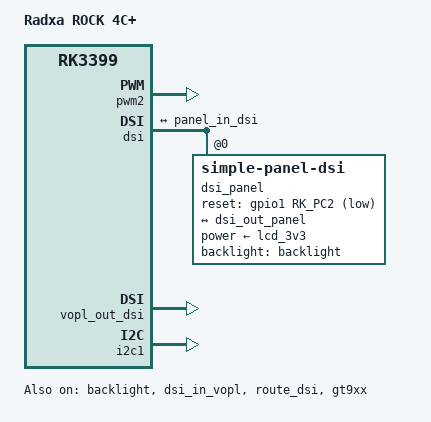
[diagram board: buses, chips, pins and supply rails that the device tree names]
/dts-v1/;
/plugin/;

#include <dt-bindings/gpio/gpio.h>
#include <dt-bindings/pinctrl/rockchip.h>
#include <dt-bindings/display/drm_mipi_dsi.h>

/ {
	model = "Radxa ROCK 4C+";
	compatible = "radxa,rock-4c-plus", "rockchip,rk3399";

	fragment@0 {
		target = <&backlight>;

		__overlay__ {
			status = "okay";
		};
	};

	fragment@1 {
		target = <&pwm2>;

		__overlay__ {
			status = "okay";
		};
	};

	fragment@2 {
		target = <&dsi>;

		__overlay__ {
			status = "okay";
			#address-cells = <1>;
			#size-cells = <0>;

			ports {
				#address-cells = <1>;
				#size-cells = <0>;

				port@1 {
					reg = <1>;
					dsi_out_panel: endpoint {
						remote-endpoint = <&panel_in_dsi>;
					};
				};
			};

			dsi_panel: dsi-panel@0 {
				status = "okay";

				compatible = "simple-panel-dsi";
				reg = <0>;

				backlight = <&backlight>;
				power-supply = <&lcd_3v3>;

				reset-gpios = <&gpio1 RK_PC2 GPIO_ACTIVE_LOW>;

				pinctrl-names = "default";
				pinctrl-0 = <&lcd_panel_reset>;

				prepare-delay-ms = <120>;
				reset-delay-ms = <120>;
				init-delay-ms = <120>;
				enable-delay-ms = <100>;
				disable-delay-ms = <120>;
				unprepare-delay-ms = <120>;

				width-mm = <62>;
				height-mm = <110>;

				dsi,flags = <(MIPI_DSI_MODE_VIDEO | MIPI_DSI_MODE_VIDEO_BURST |
						MIPI_DSI_MODE_LPM | MIPI_DSI_MODE_EOT_PACKET)>;
				dsi,format = <MIPI_DSI_FMT_RGB888>;
				dsi,lanes = <4>;

				panel-init-sequence = [
					15 00 02 E0 00
					15 00 02 E1 93
					15 00 02 E2 65
					15 00 02 E3 F8
					15 00 02 80 03
					15 00 02 E0 01
					15 00 02 00 00
					15 00 02 01 7E
					15 00 02 03 00
					15 00 02 04 65
					15 00 02 0C 74
					15 00 02 17 00
					15 00 02 18 B7
					15 00 02 19 00
					15 00 02 1A 00
					15 00 02 1B B7
					15 00 02 1C 00
					15 00 02 24 FE
					15 00 02 37 19
					15 00 02 38 05
					15 00 02 39 00
					15 00 02 3A 01
					15 00 02 3B 01
					15 00 02 3C 70
					15 00 02 3D FF
					15 00 02 3E FF
					15 00 02 3F FF
					15 00 02 40 06
					15 00 02 41 A0
					15 00 02 43 1E
					15 00 02 44 0F
					15 00 02 45 28
					15 00 02 4B 04
					15 00 02 55 02
					15 00 02 56 01
					15 00 02 57 A9
					15 00 02 58 0A
					15 00 02 59 0A
					15 00 02 5A 37
					15 00 02 5B 19
					15 00 02 5D 78
					15 00 02 5E 63
					15 00 02 5F 54
					15 00 02 60 49
					15 00 02 61 45
					15 00 02 62 38
					15 00 02 63 3D
					15 00 02 64 28
					15 00 02 65 43
					15 00 02 66 41
					15 00 02 67 43
					15 00 02 68 62
					15 00 02 69 50
					15 00 02 6A 57
					15 00 02 6B 49
					15 00 02 6C 44
					15 00 02 6D 37
					15 00 02 6E 23
					15 00 02 6F 10
					15 00 02 70 78
					15 00 02 71 63
					15 00 02 72 54
					15 00 02 73 49
					15 00 02 74 45
					15 00 02 75 38
					15 00 02 76 3D
					15 00 02 77 28
					15 00 02 78 43
					15 00 02 79 41
					15 00 02 7A 43
					15 00 02 7B 62
					15 00 02 7C 50
					15 00 02 7D 57
					15 00 02 7E 49
					15 00 02 7F 44
					15 00 02 80 37
					15 00 02 81 23
					15 00 02 82 10
					15 00 02 E0 02
					15 00 02 00 47
					15 00 02 01 47
					15 00 02 02 45
					15 00 02 03 45
					15 00 02 04 4B
					15 00 02 05 4B
					15 00 02 06 49
					15 00 02 07 49
					15 00 02 08 41
					15 00 02 09 1F
					15 00 02 0A 1F
					15 00 02 0B 1F
					15 00 02 0C 1F
					15 00 02 0D 1F
					15 00 02 0E 1F
					15 00 02 0F 5F
					15 00 02 10 5F
					15 00 02 11 57
					15 00 02 12 77
					15 00 02 13 35
					15 00 02 14 1F
					15 00 02 15 1F
					15 00 02 16 46
					15 00 02 17 46
					15 00 02 18 44
					15 00 02 19 44
					15 00 02 1A 4A
					15 00 02 1B 4A
					15 00 02 1C 48
					15 00 02 1D 48
					15 00 02 1E 40
					15 00 02 1F 1F
					15 00 02 20 1F
					15 00 02 21 1F
					15 00 02 22 1F
					15 00 02 23 1F
					15 00 02 24 1F
					15 00 02 25 5F
					15 00 02 26 5F
					15 00 02 27 57
					15 00 02 28 77
					15 00 02 29 35
					15 00 02 2A 1F
					15 00 02 2B 1F
					15 00 02 58 40
					15 00 02 59 00
					15 00 02 5A 00
					15 00 02 5B 10
					15 00 02 5C 06
					15 00 02 5D 40
					15 00 02 5E 01
					15 00 02 5F 02
					15 00 02 60 30
					15 00 02 61 01
					15 00 02 62 02
					15 00 02 63 03
					15 00 02 64 6B
					15 00 02 65 05
					15 00 02 66 0C
					15 00 02 67 73
					15 00 02 68 09
					15 00 02 69 03
					15 00 02 6A 56
					15 00 02 6B 08
					15 00 02 6C 00
					15 00 02 6D 04
					15 00 02 6E 04
					15 00 02 6F 88
					15 00 02 70 00
					15 00 02 71 00
					15 00 02 72 06
					15 00 02 73 7B
					15 00 02 74 00
					15 00 02 75 F8
					15 00 02 76 00
					15 00 02 77 D5
					15 00 02 78 2E
					15 00 02 79 12
					15 00 02 7A 03
					15 00 02 7B 00
					15 00 02 7C 00
					15 00 02 7D 03
					15 00 02 7E 7B
					15 00 02 E0 04
					15 00 02 00 0E
					15 00 02 02 B3
					15 00 02 09 60
					15 00 02 0E 2A
					15 00 02 36 59
					15 00 02 E0 00
					05 78 01 11
					05 14 01 29
				];

				panel-exit-sequence = [
					05 14 01 28
					05 78 01 10
				];

				display-timings {
					native-mode = <&timing1>;
					timing1: timing1 {
						clock-frequency = <70000000>;
						hactive = <800>;
						vactive = <1280>;

						vback-porch = <20>;
						vfront-porch = <20>;

						hback-porch = <20>;
						hfront-porch = <40>;

						hsync-len = <18>;
						vsync-len = <4>;

						vsync-active = <0>;
						hsync-active = <0>;
						de-active = <0>;
						pixelclk-active = <0>;
					};
				};

				ports {
					#address-cells = <1>;
					#size-cells = <0>;

					port@0 {
						reg = <0>;
						panel_in_dsi: endpoint {
							remote-endpoint = <&dsi_out_panel>;
						};
					};
				};
			};
		};
	};

	fragment@3 {
		target = <&vopl_out_dsi>;

		__overlay__ {
			status = "okay";
		};
	};

	fragment@4 {
		target = <&dsi_in_vopl>;

		__overlay__ {
			status = "okay";
		};
	};

	fragment@5 {
		target = <&route_dsi>;

		__overlay__ {
			status = "okay";
		};
	};

	fragment@6 {
		target = <&cdn_dp>;

		__overlay__ {
			status = "disabled";
		};
	};

	fragment@7 {
		target = <&tcphy0>;

		__overlay__ {
			status = "disabled";
		};
	};

	fragment@8 {
		target = <&dp_in_vopl>;

		__overlay__ {
			status = "disabled";
		};
	};

	fragment@9 {
		target = <&tcphy0_dp>;

		__overlay__ {
			status = "disabled";
		};
	};

	fragment@10 {
		target = <&tcphy0_usb3>;

		__overlay__ {
			status = "disabled";
		};
	};

	fragment@11 {
		target = <&i2c1>;

		__overlay__ {
			status = "okay";
		};
	};

	fragment@12 {
		target = <&gt9xx>;

		__overlay__ {
			status = "okay";
		};
	};
};
